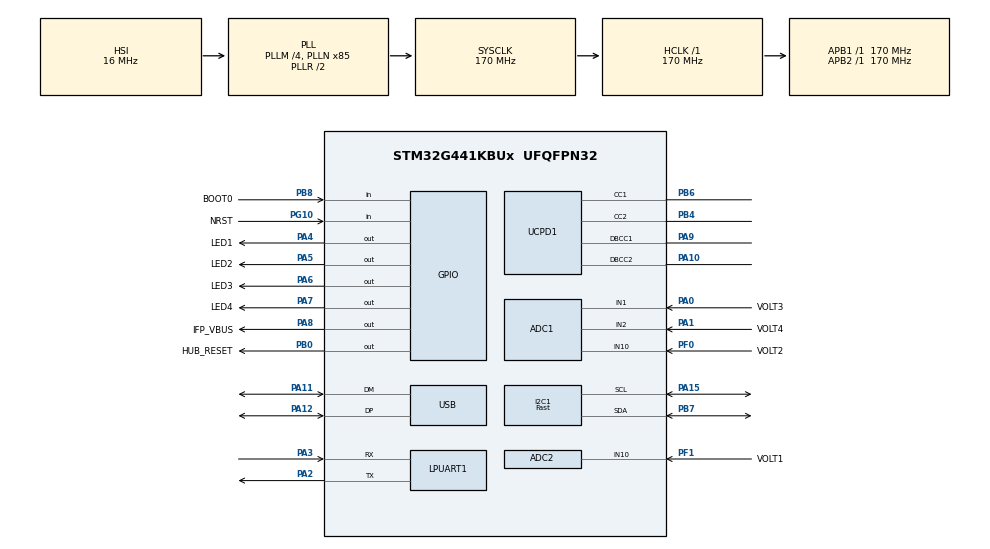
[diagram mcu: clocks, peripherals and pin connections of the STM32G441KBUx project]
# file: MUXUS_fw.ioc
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ADC1.ContinuousConvMode=DISABLE
ADC1.EnableRegularConversion=DISABLE
ADC1.Overrun=ADC_OVR_DATA_PRESERVED
ADC1.master=1
ADC2.Channel-0\#ChannelRegularConversion=ADC_CHANNEL_10
ADC2.ContinuousConvMode=ENABLE
ADC2.NbrOfConversion=1
ADC2.NbrOfConversionFlag=1
ADC2.OffsetNumber-0\#ChannelRegularConversion=ADC_OFFSET_NONE
ADC2.Overrun=ADC_OVR_DATA_OVERWRITTEN
ADC2.OversamplingMode=ENABLE
ADC2.Rank-0\#ChannelRegularConversion=1
ADC2.Ratio=ADC_OVERSAMPLING_RATIO_16
ADC2.RightBitShift=ADC_RIGHTBITSHIFT_4
ADC2.SamplingTime-0\#ChannelRegularConversion=ADC_SAMPLETIME_640CYCLES_5
Dma.ADC1.0.Direction=DMA_PERIPH_TO_MEMORY
Dma.ADC1.0.EventEnable=DISABLE
Dma.ADC1.0.Instance=DMA1_Channel1
Dma.ADC1.0.MemDataAlignment=DMA_MDATAALIGN_HALFWORD
Dma.ADC1.0.MemInc=DMA_MINC_ENABLE
Dma.ADC1.0.Mode=DMA_NORMAL
Dma.ADC1.0.PeriphDataAlignment=DMA_PDATAALIGN_HALFWORD
Dma.ADC1.0.PeriphInc=DMA_PINC_DISABLE
Dma.ADC1.0.Polarity=HAL_DMAMUX_REQ_GEN_RISING
Dma.ADC1.0.Priority=DMA_PRIORITY_LOW
Dma.ADC1.0.RequestNumber=1
Dma.ADC1.0.SignalID=NONE
Dma.ADC1.0.SyncEnable=DISABLE
Dma.ADC1.0.SyncPolarity=HAL_DMAMUX_SYNC_NO_EVENT
Dma.ADC1.0.SyncRequestNumber=1
Dma.ADC1.0.SyncSignalID=NONE
Dma.I2C1_RX.4.Direction=DMA_PERIPH_TO_MEMORY
Dma.I2C1_RX.4.EventEnable=DISABLE
Dma.I2C1_RX.4.Instance=DMA1_Channel5
Dma.I2C1_RX.4.MemDataAlignment=DMA_MDATAALIGN_BYTE
Dma.I2C1_RX.4.MemInc=DMA_MINC_ENABLE
Dma.I2C1_RX.4.Mode=DMA_NORMAL
Dma.I2C1_RX.4.PeriphDataAlignment=DMA_PDATAALIGN_BYTE
Dma.I2C1_RX.4.PeriphInc=DMA_PINC_DISABLE
Dma.I2C1_RX.4.Polarity=HAL_DMAMUX_REQ_GEN_RISING
Dma.I2C1_RX.4.Priority=DMA_PRIORITY_LOW
Dma.I2C1_RX.4.RequestNumber=1
Dma.I2C1_RX.4.SignalID=NONE
Dma.I2C1_RX.4.SyncEnable=DISABLE
Dma.I2C1_RX.4.SyncPolarity=HAL_DMAMUX_SYNC_NO_EVENT
Dma.I2C1_RX.4.SyncRequestNumber=1
Dma.I2C1_RX.4.SyncSignalID=NONE
Dma.I2C1_TX.5.Direction=DMA_MEMORY_TO_PERIPH
Dma.I2C1_TX.5.EventEnable=DISABLE
Dma.I2C1_TX.5.Instance=DMA1_Channel6
Dma.I2C1_TX.5.MemDataAlignment=DMA_MDATAALIGN_BYTE
Dma.I2C1_TX.5.MemInc=DMA_MINC_ENABLE
Dma.I2C1_TX.5.Mode=DMA_NORMAL
Dma.I2C1_TX.5.PeriphDataAlignment=DMA_PDATAALIGN_BYTE
Dma.I2C1_TX.5.PeriphInc=DMA_PINC_DISABLE
Dma.I2C1_TX.5.Polarity=HAL_DMAMUX_REQ_GEN_RISING
Dma.I2C1_TX.5.Priority=DMA_PRIORITY_LOW
Dma.I2C1_TX.5.RequestNumber=1
Dma.I2C1_TX.5.SignalID=NONE
Dma.I2C1_TX.5.SyncEnable=DISABLE
Dma.I2C1_TX.5.SyncPolarity=HAL_DMAMUX_SYNC_NO_EVENT
Dma.I2C1_TX.5.SyncRequestNumber=1
Dma.I2C1_TX.5.SyncSignalID=NONE
Dma.LPUART1_TX.1.Direction=DMA_MEMORY_TO_PERIPH
Dma.LPUART1_TX.1.EventEnable=DISABLE
Dma.LPUART1_TX.1.Instance=DMA1_Channel2
Dma.LPUART1_TX.1.MemDataAlignment=DMA_MDATAALIGN_BYTE
Dma.LPUART1_TX.1.MemInc=DMA_MINC_ENABLE
Dma.LPUART1_TX.1.Mode=DMA_NORMAL
Dma.LPUART1_TX.1.PeriphDataAlignment=DMA_PDATAALIGN_BYTE
Dma.LPUART1_TX.1.PeriphInc=DMA_PINC_DISABLE
Dma.LPUART1_TX.1.Polarity=HAL_DMAMUX_REQ_GEN_RISING
Dma.LPUART1_TX.1.Priority=DMA_PRIORITY_LOW
Dma.LPUART1_TX.1.RequestNumber=1
Dma.LPUART1_TX.1.SignalID=NONE
Dma.LPUART1_TX.1.SyncEnable=DISABLE
Dma.LPUART1_TX.1.SyncPolarity=HAL_DMAMUX_SYNC_NO_EVENT
Dma.LPUART1_TX.1.SyncRequestNumber=1
Dma.LPUART1_TX.1.SyncSignalID=NONE
Dma.Request0=ADC1
Dma.Request1=LPUART1_TX
Dma.Request2=UCPD1_RX
Dma.Request3=UCPD1_TX
Dma.Request4=I2C1_RX
Dma.Request5=I2C1_TX
Dma.UCPD1_RX.2.Direction=DMA_PERIPH_TO_MEMORY
Dma.UCPD1_RX.2.EventEnable=DISABLE
Dma.UCPD1_RX.2.Instance=DMA1_Channel3
Dma.UCPD1_RX.2.MemDataAlignment=DMA_MDATAALIGN_BYTE
Dma.UCPD1_RX.2.MemInc=DMA_MINC_ENABLE
Dma.UCPD1_RX.2.Mode=DMA_NORMAL
Dma.UCPD1_RX.2.PeriphDataAlignment=DMA_PDATAALIGN_BYTE
Dma.UCPD1_RX.2.PeriphInc=DMA_PINC_DISABLE
Dma.UCPD1_RX.2.Polarity=HAL_DMAMUX_REQ_GEN_RISING
Dma.UCPD1_RX.2.Priority=DMA_PRIORITY_LOW
Dma.UCPD1_RX.2.RequestNumber=1
Dma.UCPD1_RX.2.SignalID=NONE
Dma.UCPD1_RX.2.SyncEnable=DISABLE
Dma.UCPD1_RX.2.SyncPolarity=HAL_DMAMUX_SYNC_NO_EVENT
Dma.UCPD1_RX.2.SyncRequestNumber=1
Dma.UCPD1_RX.2.SyncSignalID=NONE
Dma.UCPD1_TX.3.Direction=DMA_MEMORY_TO_PERIPH
Dma.UCPD1_TX.3.EventEnable=DISABLE
Dma.UCPD1_TX.3.Instance=DMA1_Channel4
Dma.UCPD1_TX.3.MemDataAlignment=DMA_MDATAALIGN_BYTE
Dma.UCPD1_TX.3.MemInc=DMA_MINC_ENABLE
Dma.UCPD1_TX.3.Mode=DMA_NORMAL
Dma.UCPD1_TX.3.PeriphDataAlignment=DMA_PDATAALIGN_BYTE
Dma.UCPD1_TX.3.PeriphInc=DMA_PINC_DISABLE
Dma.UCPD1_TX.3.Polarity=HAL_DMAMUX_REQ_GEN_RISING
Dma.UCPD1_TX.3.Priority=DMA_PRIORITY_LOW
Dma.UCPD1_TX.3.RequestNumber=1
Dma.UCPD1_TX.3.SignalID=NONE
Dma.UCPD1_TX.3.SyncEnable=DISABLE
Dma.UCPD1_TX.3.SyncPolarity=HAL_DMAMUX_SYNC_NO_EVENT
Dma.UCPD1_TX.3.SyncRequestNumber=1
Dma.UCPD1_TX.3.SyncSignalID=NONE
FREERTOS.Tasks01=defaultTask,24,128,StartDefaultTask,Default,NULL,Dynamic,NULL,NULL;controlTask,24,256,controlTask_main,As external,NULL,Dynamic,NULL,NULL
FREERTOS.configLIBRARY_MAX_SYSCALL_INTERRUPT_PRIORITY=3
FREERTOS.configTOTAL_HEAP_SIZE=8192
FREERTOS.configUSE_NEWLIB_REENTRANT=1
GUI_INTERFACE.HWBoardVersionName=MUXUS
GUI_INTERFACE.PDTypeName=Sink
I2C1.I2C_Speed_Mode=I2C_Fast
I2C1.Timing=0x10802D9B
Mcu.Family=STM32G4
Mcu.Name=STM32G441KBUx
Mcu.Package=UFQFPN32
NVIC.ADC1_2_IRQn=true\:3\:0\:false\:false\:true\:true\:true\:true\:true
NVIC.DMA1_Channel1_IRQn=true\:3\:0\:false\:false\:true\:true\:false\:true\:true
NVIC.DMA1_Channel2_IRQn=true\:3\:0\:false\:false\:true\:true\:false\:true\:true
NVIC.DMA1_Channel3_IRQn=true\:3\:0\:false\:false\:true\:true\:false\:true\:true
NVIC.DMA1_Channel4_IRQn=true\:3\:0\:false\:false\:true\:true\:false\:true\:true
NVIC.DMA1_Channel5_IRQn=true\:3\:0\:false\:false\:true\:true\:false\:true\:true
NVIC.DMA1_Channel6_IRQn=true\:3\:0\:false\:false\:true\:true\:false\:true\:true
NVIC.I2C1_ER_IRQn=true\:3\:0\:false\:false\:true\:true\:true\:true\:true
NVIC.I2C1_EV_IRQn=true\:3\:0\:false\:false\:true\:true\:true\:true\:true
NVIC.LPUART1_IRQn=true\:3\:0\:false\:false\:true\:true\:true\:true\:true
NVIC.PriorityGroup=NVIC_PRIORITYGROUP_4
NVIC.TIM6_DAC_IRQn=true\:15\:0\:false\:false\:true\:false\:false\:true\:true
NVIC.TimeBase=TIM6_DAC_IRQn
NVIC.TimeBaseIP=TIM6
NVIC.UCPD1_IRQn=true\:3\:0\:false\:false\:true\:true\:true\:false\:true
NVIC.USB_HP_IRQn=true\:3\:0\:false\:false\:true\:true\:true\:true\:true
NVIC.USB_LP_IRQn=true\:3\:0\:false\:false\:true\:true\:true\:true\:true
PA0.GPIO_Label=VOLT3
PA0.Mode=IN1-Single-Ended
PA0.Signal=ADC1_IN1
PA1.GPIO_Label=VOLT4
PA1.Mode=IN2-Single-Ended
PA1.Signal=ADC1_IN2
PA10.Mode=EnableDeadBattery
PA10.Signal=UCPD1_DBCC2
PA11.Mode=Device
PA11.Signal=USB_DM
PA12.Mode=Device
PA12.Signal=USB_DP
PA13.Mode=Trace_Asynchronous_SW
PA13.Signal=SYS_JTMS-SWDIO
PA14.Mode=Trace_Asynchronous_SW
PA14.Signal=SYS_JTCK-SWCLK
PA15.Mode=I2C
PA15.Signal=I2C1_SCL
PA2.Mode=Asynchronous
PA2.Signal=LPUART1_TX
PA3.Mode=Asynchronous
PA3.Signal=LPUART1_RX
PA4.GPIO_Label=LED1
PA4.GPIO_ModeDefaultOutputPP=GPIO_MODE_OUTPUT_OD
PA4.PinState=GPIO_PIN_SET
PA4.Signal=GPIO_Output
PA5.GPIO_Label=LED2
PA5.GPIO_ModeDefaultOutputPP=GPIO_MODE_OUTPUT_OD
PA5.PinState=GPIO_PIN_SET
PA5.Signal=GPIO_Output
PA6.GPIO_Label=LED3
PA6.GPIO_ModeDefaultOutputPP=GPIO_MODE_OUTPUT_OD
PA6.PinState=GPIO_PIN_SET
PA6.Signal=GPIO_Output
PA7.GPIO_Label=LED4
PA7.GPIO_ModeDefaultOutputPP=GPIO_MODE_OUTPUT_OD
PA7.PinState=GPIO_PIN_SET
PA7.Signal=GPIO_Output
PA8.GPIO_Label=IFP_VBUS
PA8.GPIO_ModeDefaultOutputPP=GPIO_MODE_OUTPUT_OD
PA8.PinState=GPIO_PIN_SET
PA8.Signal=GPIO_Output
PA9.Mode=EnableDeadBattery
PA9.Signal=UCPD1_DBCC1
PB0.GPIO_Label=HUB_RESET
PB0.GPIO_ModeDefaultOutputPP=GPIO_MODE_OUTPUT_OD
PB0.PinState=GPIO_PIN_SET
PB0.Signal=GPIO_Output
PB3.Mode=Trace_Asynchronous_SW
PB3.Signal=SYS_JTDO-SWO
PB4.Mode=Sink_AllSignals
PB4.Signal=UCPD1_CC2
PB5.Signal=I2C1_SMBA
PB6.Mode=Sink_AllSignals
PB6.Signal=UCPD1_CC1
PB7.Mode=I2C
PB7.Signal=I2C1_SDA
PB8-BOOT0.GPIO_Label=BOOT0
PB8-BOOT0.Signal=GPIO_Input
PF0-OSC_IN.GPIO_Label=VOLT2
PF0-OSC_IN.Mode=IN10-Single-Ended
PF0-OSC_IN.Signal=ADC1_IN10
PF1-OSC_OUT.GPIO_Label=VOLT1
PF1-OSC_OUT.Mode=IN10-Single-Ended
PF1-OSC_OUT.Signal=ADC2_IN10
PG10-NRST.GPIO_Label=NRST
PG10-NRST.Signal=GPIO_Input
ProjectManager.HeapSize=0x500
ProjectManager.StackSize=0x400
ProjectManager.TargetToolchain=STM32CubeIDE
RCC.ADC12Freq_Value=170000000
RCC.AHBFreq_Value=170000000
RCC.APB1Freq_Value=170000000
RCC.APB1TimFreq_Value=170000000
RCC.APB2Freq_Value=170000000
RCC.APB2TimFreq_Value=170000000
RCC.CK48CLockSelection=RCC_USBCLKSOURCE_HSI48
RCC.CortexFreq_Value=170000000
RCC.EXTERNAL_CLOCK_VALUE=12288000
RCC.HCLKFreq_Value=170000000
RCC.HSE_VALUE=8000000
RCC.HSI48_VALUE=48000000
RCC.HSI_VALUE=16000000
RCC.LSE_VALUE=32768
RCC.PLLM=RCC_PLLM_DIV4
RCC.PLLN=85
RCC.SYSCLKFreq_VALUE=170000000
RCC.SYSCLKSource=RCC_SYSCLKSOURCE_PLLCLK
RCC.USBFreq_Value=48000000
RCC.VCOOutputFreq_Value=340000000
USBPD.PE_SpecRevision_P0=USBPD_SPECIFICATION_REV3
USBPD.PORT0_SINK_PDO1=0x260190C8
USBPD.USBPD_PORT0_PDO_SNK_FIXED_SET_OP_CURRENT_0=1500
USB_DEVICE.CLASS_NAME_FS=MSC
USB_DEVICE.PRODUCT_STRING_MSC_FS=MUXUS
USB_DEVICE.VirtualMode=Msc
USB_DEVICE.VirtualModeFS=Msc_FS
VP_FREERTOS_VS_CMSIS_V2.Mode=CMSIS_V2
VP_GUI_INTERFACE_VS_gui_interface.Mode=GUI_INTERFACE
VP_RCC_VS_USB.Mode=USB_FS
VP_SYS_VS_DBSignals.Mode=DisableDeadBatterySignals
VP_SYS_VS_tim6.Mode=TIM6
VP_TRACER_EMB_VS_traceremb_lpuart1.Mode=TRACER_EMB_LPUART1
VP_USBPD_VS_PD3FULL.Mode=PD3_Full_Stack
VP_USBPD_VS_USBPD1.Mode=USBPD_P0
VP_USBPD_VS_usbpd_tim1.Mode=TIM1
VP_USBPD_VS_usbpd_traceremb.Mode=TRACER_EMB
VP_USB_DEVICE_VS_USB_DEVICE_MSC_FS.Mode=MSC_FS
board=custom

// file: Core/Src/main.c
/* USER CODE BEGIN Header */
/**
  ******************************************************************************
  * @file           : main.c
  * @brief          : Main program body
  ******************************************************************************
  * @attention
  *
  * <h2><center>&copy; Copyright (c) 2021 STMicroelectronics.
  * All rights reserved.</center></h2>
  *
  * This software component is licensed by ST under BSD 3-Clause license,
  * the "License"; You may not use this file except in compliance with the
  * License. You may obtain a copy of the License at:
  *                        opensource.org/licenses/BSD-3-Clause
  *
  ******************************************************************************
  */
/* USER CODE END Header */
#include "main.h"
#include "cmsis_os.h"
#include "usbpd.h"
#include "usb_device.h"

/* USER CODE BEGIN Includes */

#include <bootapp.h>

/* USER CODE END Includes */

ADC_HandleTypeDef hadc1;
ADC_HandleTypeDef hadc2;
DMA_HandleTypeDef hdma_adc1;

I2C_HandleTypeDef hi2c1;
DMA_HandleTypeDef hdma_i2c1_rx;
DMA_HandleTypeDef hdma_i2c1_tx;

/* Definitions for defaultTask */
osThreadId_t defaultTaskHandle;
const osThreadAttr_t defaultTask_attributes = {
  .name = "defaultTask",
  .priority = (osPriority_t) osPriorityNormal,
  .stack_size = 128 * 4
};
/* Definitions for controlTask */
osThreadId_t controlTaskHandle;
const osThreadAttr_t controlTask_attributes = {
  .name = "controlTask",
  .priority = (osPriority_t) osPriorityNormal,
  .stack_size = 256 * 4
};

void SystemClock_Config(void);
static void MX_GPIO_Init(void);
static void MX_DMA_Init(void);
static void MX_ADC1_Init(void);
static void MX_ADC2_Init(void);
static void MX_I2C1_Init(void);
static void MX_LPUART1_UART_Init(void);
static void MX_UCPD1_Init(void);
void StartDefaultTask(void *argument);
extern void controlTask_main(void *argument);

int main(void)
{
  /* USER CODE BEGIN 1 */
  bootapp();
  /* USER CODE END 1 */

  /* MCU Configuration--------------------------------------------------------*/

  /* Reset of all peripherals, Initializes the Flash interface and the Systick. */
  HAL_Init();

  /* Configure the system clock */
  SystemClock_Config();

  /* Initialize all configured peripherals */
  MX_GPIO_Init();
  MX_DMA_Init();
  MX_ADC1_Init();
  MX_ADC2_Init();
  MX_I2C1_Init();
  MX_LPUART1_UART_Init();
  MX_UCPD1_Init();
  MX_USB_Device_Init();

  /* Init scheduler */
  osKernelInitialize();
  /* USBPD initialisation ---------------------------------*/
  MX_USBPD_Init();

  /* Create the thread(s) */
  /* creation of defaultTask */
  defaultTaskHandle = osThreadNew(StartDefaultTask, NULL, &defaultTask_attributes);

  /* creation of controlTask */
  controlTaskHandle = osThreadNew(controlTask_main, NULL, &controlTask_attributes);

  /* Start scheduler */
  osKernelStart();

  /* We should never get here as control is now taken by the scheduler */
  /* Infinite loop */
  while (1)
  {

  }
}

void SystemClock_Config(void)
{
  RCC_OscInitTypeDef RCC_OscInitStruct = {0};
  RCC_ClkInitTypeDef RCC_ClkInitStruct = {0};
  RCC_CRSInitTypeDef pInit = {0};

  /** Configure the main internal regulator output voltage
  */
  HAL_PWREx_ControlVoltageScaling(PWR_REGULATOR_VOLTAGE_SCALE1_BOOST);

  /** Initializes the RCC Oscillators according to the specified parameters
  * in the RCC_OscInitTypeDef structure.
  */
  RCC_OscInitStruct.OscillatorType = RCC_OSCILLATORTYPE_HSI|RCC_OSCILLATORTYPE_HSI48;
  RCC_OscInitStruct.HSIState = RCC_HSI_ON;
  RCC_OscInitStruct.HSICalibrationValue = RCC_HSICALIBRATION_DEFAULT;
  RCC_OscInitStruct.HSI48State = RCC_HSI48_ON;
  RCC_OscInitStruct.PLL.PLLState = RCC_PLL_ON;
  RCC_OscInitStruct.PLL.PLLSource = RCC_PLLSOURCE_HSI;
  RCC_OscInitStruct.PLL.PLLM = RCC_PLLM_DIV4;
  RCC_OscInitStruct.PLL.PLLN = 85;
  RCC_OscInitStruct.PLL.PLLP = RCC_PLLP_DIV2;
  RCC_OscInitStruct.PLL.PLLQ = RCC_PLLQ_DIV2;
  RCC_OscInitStruct.PLL.PLLR = RCC_PLLR_DIV2;
  if (HAL_RCC_OscConfig(&RCC_OscInitStruct) != HAL_OK)
  {
    Error_Handler();
  }

  /** Initializes the CPU, AHB and APB buses clocks
  */
  RCC_ClkInitStruct.ClockType = RCC_CLOCKTYPE_HCLK|RCC_CLOCKTYPE_SYSCLK
                              |RCC_CLOCKTYPE_PCLK1|RCC_CLOCKTYPE_PCLK2;
  RCC_ClkInitStruct.SYSCLKSource = RCC_SYSCLKSOURCE_PLLCLK;
  RCC_ClkInitStruct.AHBCLKDivider = RCC_SYSCLK_DIV1;
  RCC_ClkInitStruct.APB1CLKDivider = RCC_HCLK_DIV1;
  RCC_ClkInitStruct.APB2CLKDivider = RCC_HCLK_DIV1;

  if (HAL_RCC_ClockConfig(&RCC_ClkInitStruct, FLASH_LATENCY_4) != HAL_OK)
  {
    Error_Handler();
  }

  /** Enable the SYSCFG APB clock
  */
  __HAL_RCC_CRS_CLK_ENABLE();

  /** Configures CRS
  */
  pInit.Prescaler = RCC_CRS_SYNC_DIV1;
  pInit.Source = RCC_CRS_SYNC_SOURCE_USB;
  pInit.Polarity = RCC_CRS_SYNC_POLARITY_RISING;
  pInit.ReloadValue = __HAL_RCC_CRS_RELOADVALUE_CALCULATE(48000000,1000);
  pInit.ErrorLimitValue = 34;
  pInit.HSI48CalibrationValue = 32;

  HAL_RCCEx_CRSConfig(&pInit);
}

static void MX_ADC1_Init(void)
{

  ADC_MultiModeTypeDef multimode = {0};

  /** Common config
  */
  hadc1.Instance = ADC1;
  hadc1.Init.ClockPrescaler = ADC_CLOCK_SYNC_PCLK_DIV4;
  hadc1.Init.Resolution = ADC_RESOLUTION_12B;
  hadc1.Init.DataAlign = ADC_DATAALIGN_RIGHT;
  hadc1.Init.GainCompensation = 0;
  hadc1.Init.ScanConvMode = ADC_SCAN_DISABLE;
  hadc1.Init.EOCSelection = ADC_EOC_SINGLE_CONV;
  hadc1.Init.LowPowerAutoWait = DISABLE;
  hadc1.Init.ContinuousConvMode = DISABLE;
  hadc1.Init.NbrOfConversion = 1;
  hadc1.Init.DiscontinuousConvMode = DISABLE;
  hadc1.Init.DMAContinuousRequests = DISABLE;
  hadc1.Init.Overrun = ADC_OVR_DATA_PRESERVED;
  hadc1.Init.OversamplingMode = DISABLE;
  if (HAL_ADC_Init(&hadc1) != HAL_OK)
  {
    Error_Handler();
  }

  /** Configure the ADC multi-mode
  */
  multimode.Mode = ADC_MODE_INDEPENDENT;
  if (HAL_ADCEx_MultiModeConfigChannel(&hadc1, &multimode) != HAL_OK)
  {
    Error_Handler();
  }

}

static void MX_ADC2_Init(void)
{

  ADC_ChannelConfTypeDef sConfig = {0};

  /** Common config
  */
  hadc2.Instance = ADC2;
  hadc2.Init.ClockPrescaler = ADC_CLOCK_SYNC_PCLK_DIV4;
  hadc2.Init.Resolution = ADC_RESOLUTION_12B;
  hadc2.Init.DataAlign = ADC_DATAALIGN_RIGHT;
  hadc2.Init.GainCompensation = 0;
  hadc2.Init.ScanConvMode = ADC_SCAN_DISABLE;
  hadc2.Init.EOCSelection = ADC_EOC_SINGLE_CONV;
  hadc2.Init.LowPowerAutoWait = DISABLE;
  hadc2.Init.ContinuousConvMode = ENABLE;
  hadc2.Init.NbrOfConversion = 1;
  hadc2.Init.DiscontinuousConvMode = DISABLE;
  hadc2.Init.ExternalTrigConv = ADC_SOFTWARE_START;
  hadc2.Init.ExternalTrigConvEdge = ADC_EXTERNALTRIGCONVEDGE_NONE;
  hadc2.Init.DMAContinuousRequests = DISABLE;
  hadc2.Init.Overrun = ADC_OVR_DATA_OVERWRITTEN;
  hadc2.Init.OversamplingMode = ENABLE;
  hadc2.Init.Oversampling.Ratio = ADC_OVERSAMPLING_RATIO_16;
  hadc2.Init.Oversampling.RightBitShift = ADC_RIGHTBITSHIFT_4;
  hadc2.Init.Oversampling.TriggeredMode = ADC_TRIGGEREDMODE_SINGLE_TRIGGER;
  hadc2.Init.Oversampling.OversamplingStopReset = ADC_REGOVERSAMPLING_CONTINUED_MODE;
  if (HAL_ADC_Init(&hadc2) != HAL_OK)
  {
    Error_Handler();
  }

  /** Configure Regular Channel
  */
  sConfig.Channel = ADC_CHANNEL_10;
  sConfig.Rank = ADC_REGULAR_RANK_1;
  sConfig.SamplingTime = ADC_SAMPLETIME_640CYCLES_5;
  sConfig.SingleDiff = ADC_SINGLE_ENDED;
  sConfig.OffsetNumber = ADC_OFFSET_NONE;
  sConfig.Offset = 0;
  if (HAL_ADC_ConfigChannel(&hadc2, &sConfig) != HAL_OK)
  {
    Error_Handler();
  }
  /* USER CODE BEGIN ADC2_Init 2 */
  HAL_ADCEx_Calibration_Start(&hadc2, ADC_SINGLE_ENDED);
  HAL_ADC_Start(&hadc2);
  /* USER CODE END ADC2_Init 2 */

}

static void MX_I2C1_Init(void)
{

  hi2c1.Instance = I2C1;
  hi2c1.Init.Timing = 0x10802D9B;
  hi2c1.Init.OwnAddress1 = 0;
  hi2c1.Init.AddressingMode = I2C_ADDRESSINGMODE_7BIT;
  hi2c1.Init.DualAddressMode = I2C_DUALADDRESS_DISABLE;
  hi2c1.Init.OwnAddress2 = 0;
  hi2c1.Init.OwnAddress2Masks = I2C_OA2_NOMASK;
  hi2c1.Init.GeneralCallMode = I2C_GENERALCALL_DISABLE;
  hi2c1.Init.NoStretchMode = I2C_NOSTRETCH_DISABLE;
  if (HAL_I2C_Init(&hi2c1) != HAL_OK)
  {
    Error_Handler();
  }

  /** Configure Analogue filter
  */
  if (HAL_I2CEx_ConfigAnalogFilter(&hi2c1, I2C_ANALOGFILTER_ENABLE) != HAL_OK)
  {
    Error_Handler();
  }

  /** Configure Digital filter
  */
  if (HAL_I2CEx_ConfigDigitalFilter(&hi2c1, 0) != HAL_OK)
  {
    Error_Handler();
  }

}

static void MX_LPUART1_UART_Init(void)
{

  LL_LPUART_InitTypeDef LPUART_InitStruct = {0};

  LL_GPIO_InitTypeDef GPIO_InitStruct = {0};
  RCC_PeriphCLKInitTypeDef PeriphClkInit = {0};

  /** Initializes the peripherals clocks
  */
  PeriphClkInit.PeriphClockSelection = RCC_PERIPHCLK_LPUART1;
  PeriphClkInit.Lpuart1ClockSelection = RCC_LPUART1CLKSOURCE_PCLK1;
  if (HAL_RCCEx_PeriphCLKConfig(&PeriphClkInit) != HAL_OK)
  {
    Error_Handler();
  }

  /* Peripheral clock enable */
  LL_APB1_GRP2_EnableClock(LL_APB1_GRP2_PERIPH_LPUART1);

  LL_AHB2_GRP1_EnableClock(LL_AHB2_GRP1_PERIPH_GPIOA);
  /**LPUART1 GPIO Configuration
  PA2   ------> LPUART1_TX
  PA3   ------> LPUART1_RX
  */
  GPIO_InitStruct.Pin = LL_GPIO_PIN_2;
  GPIO_InitStruct.Mode = LL_GPIO_MODE_ALTERNATE;
  GPIO_InitStruct.Speed = LL_GPIO_SPEED_FREQ_LOW;
  GPIO_InitStruct.OutputType = LL_GPIO_OUTPUT_PUSHPULL;
  GPIO_InitStruct.Pull = LL_GPIO_PULL_NO;
  GPIO_InitStruct.Alternate = LL_GPIO_AF_12;
  LL_GPIO_Init(GPIOA, &GPIO_InitStruct);

  GPIO_InitStruct.Pin = LL_GPIO_PIN_3;
  GPIO_InitStruct.Mode = LL_GPIO_MODE_ALTERNATE;
  GPIO_InitStruct.Speed = LL_GPIO_SPEED_FREQ_LOW;
  GPIO_InitStruct.OutputType = LL_GPIO_OUTPUT_PUSHPULL;
  GPIO_InitStruct.Pull = LL_GPIO_PULL_NO;
  GPIO_InitStruct.Alternate = LL_GPIO_AF_12;
  LL_GPIO_Init(GPIOA, &GPIO_InitStruct);

  /* LPUART1 DMA Init */

  /* LPUART1_TX Init */
  LL_DMA_SetPeriphRequest(DMA1, LL_DMA_CHANNEL_2, LL_DMAMUX_REQ_LPUART1_TX);

  LL_DMA_SetDataTransferDirection(DMA1, LL_DMA_CHANNEL_2, LL_DMA_DIRECTION_MEMORY_TO_PERIPH);

  LL_DMA_SetChannelPriorityLevel(DMA1, LL_DMA_CHANNEL_2, LL_DMA_PRIORITY_LOW);

  LL_DMA_SetMode(DMA1, LL_DMA_CHANNEL_2, LL_DMA_MODE_NORMAL);

  LL_DMA_SetPeriphIncMode(DMA1, LL_DMA_CHANNEL_2, LL_DMA_PERIPH_NOINCREMENT);

  LL_DMA_SetMemoryIncMode(DMA1, LL_DMA_CHANNEL_2, LL_DMA_MEMORY_INCREMENT);

  LL_DMA_SetPeriphSize(DMA1, LL_DMA_CHANNEL_2, LL_DMA_PDATAALIGN_BYTE);

  LL_DMA_SetMemorySize(DMA1, LL_DMA_CHANNEL_2, LL_DMA_MDATAALIGN_BYTE);

  /* LPUART1 interrupt Init */
  NVIC_SetPriority(LPUART1_IRQn, NVIC_EncodePriority(NVIC_GetPriorityGrouping(),3, 0));
  NVIC_EnableIRQ(LPUART1_IRQn);

  LPUART_InitStruct.PrescalerValue = LL_LPUART_PRESCALER_DIV1;
  LPUART_InitStruct.BaudRate = 921600;
  LPUART_InitStruct.DataWidth = LL_LPUART_DATAWIDTH_8B;
  LPUART_InitStruct.StopBits = LL_LPUART_STOPBITS_1;
  LPUART_InitStruct.Parity = LL_LPUART_PARITY_NONE;
  LPUART_InitStruct.TransferDirection = LL_LPUART_DIRECTION_TX_RX;
  LPUART_InitStruct.HardwareFlowControl = LL_LPUART_HWCONTROL_NONE;
  LL_LPUART_Init(LPUART1, &LPUART_InitStruct);
  LL_LPUART_SetTXFIFOThreshold(LPUART1, LL_LPUART_FIFOTHRESHOLD_1_8);
  LL_LPUART_SetRXFIFOThreshold(LPUART1, LL_LPUART_FIFOTHRESHOLD_1_8);
  LL_LPUART_DisableFIFO(LPUART1);

  LL_LPUART_Enable(LPUART1);

  /* Polling LPUART1 initialisation */
  while((!(LL_LPUART_IsActiveFlag_TEACK(LPUART1))) || (!(LL_LPUART_IsActiveFlag_REACK(LPUART1))))
  {
  }

}

static void MX_UCPD1_Init(void)
{

  LL_GPIO_InitTypeDef GPIO_InitStruct = {0};

  /* Peripheral clock enable */
  LL_APB1_GRP2_EnableClock(LL_APB1_GRP2_PERIPH_UCPD1);

  LL_AHB2_GRP1_EnableClock(LL_AHB2_GRP1_PERIPH_GPIOB);
  /**UCPD1 GPIO Configuration
  PB4   ------> UCPD1_CC2
  PB6   ------> UCPD1_CC1
  */
  GPIO_InitStruct.Pin = LL_GPIO_PIN_4;
  GPIO_InitStruct.Mode = LL_GPIO_MODE_ANALOG;
  GPIO_InitStruct.Pull = LL_GPIO_PULL_NO;
  LL_GPIO_Init(GPIOB, &GPIO_InitStruct);

  GPIO_InitStruct.Pin = LL_GPIO_PIN_6;
  GPIO_InitStruct.Mode = LL_GPIO_MODE_ANALOG;
  GPIO_InitStruct.Pull = LL_GPIO_PULL_NO;
  LL_GPIO_Init(GPIOB, &GPIO_InitStruct);

  /* UCPD1 DMA Init */

  /* UCPD1_RX Init */
  LL_DMA_SetPeriphRequest(DMA1, LL_DMA_CHANNEL_3, LL_DMAMUX_REQ_UCPD1_RX);

  LL_DMA_SetDataTransferDirection(DMA1, LL_DMA_CHANNEL_3, LL_DMA_DIRECTION_PERIPH_TO_MEMORY);

  LL_DMA_SetChannelPriorityLevel(DMA1, LL_DMA_CHANNEL_3, LL_DMA_PRIORITY_LOW);

  LL_DMA_SetMode(DMA1, LL_DMA_CHANNEL_3, LL_DMA_MODE_NORMAL);

  LL_DMA_SetPeriphIncMode(DMA1, LL_DMA_CHANNEL_3, LL_DMA_PERIPH_NOINCREMENT);

  LL_DMA_SetMemoryIncMode(DMA1, LL_DMA_CHANNEL_3, LL_DMA_MEMORY_INCREMENT);

  LL_DMA_SetPeriphSize(DMA1, LL_DMA_CHANNEL_3, LL_DMA_PDATAALIGN_BYTE);

  LL_DMA_SetMemorySize(DMA1, LL_DMA_CHANNEL_3, LL_DMA_MDATAALIGN_BYTE);

  /* UCPD1_TX Init */
  LL_DMA_SetPeriphRequest(DMA1, LL_DMA_CHANNEL_4, LL_DMAMUX_REQ_UCPD1_TX);

  LL_DMA_SetDataTransferDirection(DMA1, LL_DMA_CHANNEL_4, LL_DMA_DIRECTION_MEMORY_TO_PERIPH);

  LL_DMA_SetChannelPriorityLevel(DMA1, LL_DMA_CHANNEL_4, LL_DMA_PRIORITY_LOW);

  LL_DMA_SetMode(DMA1, LL_DMA_CHANNEL_4, LL_DMA_MODE_NORMAL);

  LL_DMA_SetPeriphIncMode(DMA1, LL_DMA_CHANNEL_4, LL_DMA_PERIPH_NOINCREMENT);

  LL_DMA_SetMemoryIncMode(DMA1, LL_DMA_CHANNEL_4, LL_DMA_MEMORY_INCREMENT);

  LL_DMA_SetPeriphSize(DMA1, LL_DMA_CHANNEL_4, LL_DMA_PDATAALIGN_BYTE);

  LL_DMA_SetMemorySize(DMA1, LL_DMA_CHANNEL_4, LL_DMA_MDATAALIGN_BYTE);

  /* UCPD1 interrupt Init */
  NVIC_SetPriority(UCPD1_IRQn, NVIC_EncodePriority(NVIC_GetPriorityGrouping(),3, 0));
  NVIC_EnableIRQ(UCPD1_IRQn);

}

static void MX_DMA_Init(void)
{

  /* DMA controller clock enable */
  __HAL_RCC_DMAMUX1_CLK_ENABLE();
  __HAL_RCC_DMA1_CLK_ENABLE();

  /* DMA interrupt init */
  /* DMA1_Channel1_IRQn interrupt configuration */
  HAL_NVIC_SetPriority(DMA1_Channel1_IRQn, 3, 0);
  HAL_NVIC_EnableIRQ(DMA1_Channel1_IRQn);
  /* DMA1_Channel2_IRQn interrupt configuration */
  NVIC_SetPriority(DMA1_Channel2_IRQn, NVIC_EncodePriority(NVIC_GetPriorityGrouping(),3, 0));
  NVIC_EnableIRQ(DMA1_Channel2_IRQn);
  /* DMA1_Channel3_IRQn interrupt configuration */
  NVIC_SetPriority(DMA1_Channel3_IRQn, NVIC_EncodePriority(NVIC_GetPriorityGrouping(),3, 0));
  NVIC_EnableIRQ(DMA1_Channel3_IRQn);
  /* DMA1_Channel4_IRQn interrupt configuration */
  NVIC_SetPriority(DMA1_Channel4_IRQn, NVIC_EncodePriority(NVIC_GetPriorityGrouping(),3, 0));
  NVIC_EnableIRQ(DMA1_Channel4_IRQn);
  /* DMA1_Channel5_IRQn interrupt configuration */
  HAL_NVIC_SetPriority(DMA1_Channel5_IRQn, 3, 0);
  HAL_NVIC_EnableIRQ(DMA1_Channel5_IRQn);
  /* DMA1_Channel6_IRQn interrupt configuration */
  HAL_NVIC_SetPriority(DMA1_Channel6_IRQn, 3, 0);
  HAL_NVIC_EnableIRQ(DMA1_Channel6_IRQn);

}

static void MX_GPIO_Init(void)
{
  GPIO_InitTypeDef GPIO_InitStruct = {0};

  /* GPIO Ports Clock Enable */
  __HAL_RCC_GPIOF_CLK_ENABLE();
  __HAL_RCC_GPIOG_CLK_ENABLE();
  __HAL_RCC_GPIOA_CLK_ENABLE();
  __HAL_RCC_GPIOB_CLK_ENABLE();

  /*Configure GPIO pin Output Level */
  HAL_GPIO_WritePin(GPIOA, LED1_Pin|LED2_Pin|LED3_Pin|LED4_Pin
                          |IFP_VBUS_Pin, GPIO_PIN_SET);

  /*Configure GPIO pin Output Level */
  HAL_GPIO_WritePin(HUB_RESET_GPIO_Port, HUB_RESET_Pin, GPIO_PIN_SET);

  /*Configure GPIO pin : NRST_Pin */
  GPIO_InitStruct.Pin = NRST_Pin;
  GPIO_InitStruct.Mode = GPIO_MODE_INPUT;
  GPIO_InitStruct.Pull = GPIO_NOPULL;
  HAL_GPIO_Init(NRST_GPIO_Port, &GPIO_InitStruct);

  /*Configure GPIO pins : LED1_Pin LED2_Pin LED3_Pin LED4_Pin
                           IFP_VBUS_Pin */
  GPIO_InitStruct.Pin = LED1_Pin|LED2_Pin|LED3_Pin|LED4_Pin
                          |IFP_VBUS_Pin;
  GPIO_InitStruct.Mode = GPIO_MODE_OUTPUT_OD;
  GPIO_InitStruct.Pull = GPIO_NOPULL;
  GPIO_InitStruct.Speed = GPIO_SPEED_FREQ_LOW;
  HAL_GPIO_Init(GPIOA, &GPIO_InitStruct);

  /*Configure GPIO pin : HUB_RESET_Pin */
  GPIO_InitStruct.Pin = HUB_RESET_Pin;
  GPIO_InitStruct.Mode = GPIO_MODE_OUTPUT_OD;
  GPIO_InitStruct.Pull = GPIO_NOPULL;
  GPIO_InitStruct.Speed = GPIO_SPEED_FREQ_LOW;
  HAL_GPIO_Init(HUB_RESET_GPIO_Port, &GPIO_InitStruct);

  /*Configure GPIO pin : BOOT0_Pin */
  GPIO_InitStruct.Pin = BOOT0_Pin;
  GPIO_InitStruct.Mode = GPIO_MODE_INPUT;
  GPIO_InitStruct.Pull = GPIO_NOPULL;
  HAL_GPIO_Init(BOOT0_GPIO_Port, &GPIO_InitStruct);

}

void StartDefaultTask(void *argument)
{
	for (;;)
		osDelay(1);
}

void HAL_TIM_PeriodElapsedCallback(TIM_HandleTypeDef *htim)
{
  if (htim->Instance == TIM6) {
    HAL_IncTick();
  }
  /* USER CODE BEGIN Callback 1 */
#ifdef _GUI_INTERFACE
  if (htim->Instance == TIM6) {
	  GUI_TimerCounter();
  }
#endif
  /* USER CODE END Callback 1 */
}

void Error_Handler(void)
{
  __disable_irq();
  while (1)
  {
  }
}
